# STM32F303 register map
File version: 1.8
CPU: CM4 r1p0, little endian, MPU, FPU, 3 interrupt priority bits
Registers are 32-bit, read-write, reset 0x0 unless marked. A register's access mark holds for its fields unless they carry their own. Offsets are from the block's base; [hi:lo] are bit positions; {n}, {i} and the like mark numbered series; 'fields as' and 'values as' point back to an identical list.

## ADC1_2 — Analog-to-Digital Converter
Base 0x50000300
Same registers: ADC3_4 0x50000700
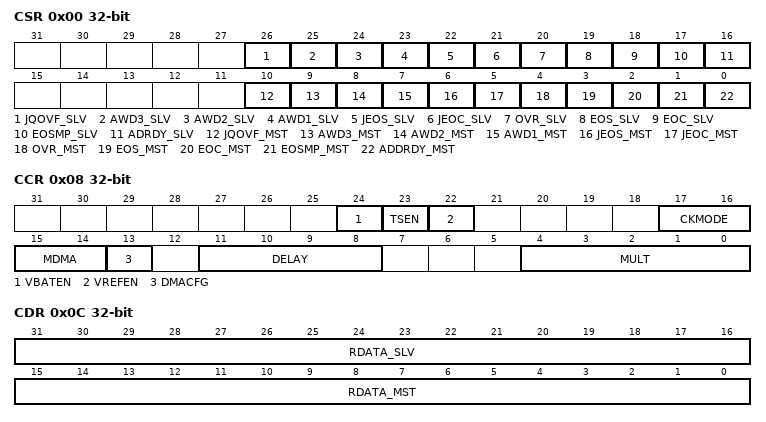
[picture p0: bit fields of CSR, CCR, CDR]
0x00 CSR ro — ADC Common status register
  [26] JQOVF_SLV — Injected Context Queue Overflow flag of the slave ADC
  [25] AWD3_SLV — Analog watchdog 3 flag of the slave ADC
  [24] AWD2_SLV — Analog watchdog 2 flag of the slave ADC
  [23] AWD1_SLV — Analog watchdog 1 flag of the slave ADC
  [22] JEOS_SLV — End of injected sequence flag of the slave ADC
  [21] JEOC_SLV — End of injected conversion flag of the slave ADC
  [20] OVR_SLV — Overrun flag of the slave ADC
  [19] EOS_SLV — End of regular sequence flag of the slave ADC
  [18] EOC_SLV — End of regular conversion of the slave ADC
  [17] EOSMP_SLV
  [16] ADRDY_SLV
  [10] JQOVF_MST
  [9] AWD3_MST
  [8] AWD2_MST
  [7] AWD1_MST
  [6] JEOS_MST
  [5] JEOC_MST
  [4] OVR_MST
  [3] EOS_MST
  [2] EOC_MST
  [1] EOSMP_MST
  [0] ADDRDY_MST
0x08 CCR — ADC common control register
  [24] VBATEN — VBAT enable
  [23] TSEN — Temperature sensor enable
  [22] VREFEN — VREFINT enable
  [17:16] CKMODE — ADC clock mode
  [15:14] MDMA — Direct memory access mode for multi ADC mode
  [13] DMACFG — DMA configuration (for multi-ADC mode)
  [11:8] DELAY — Delay between 2 sampling phases
  [4:0] MULT — Multi ADC mode selection
0x0C CDR ro — ADC common regular data register for dual and triple modes
  [31:16] RDATA_SLV — Regular data of the slave ADC
  [15:0] RDATA_MST — Regular data of the master ADC

## FMC — Flexible memory controller
Base 0xA0000400
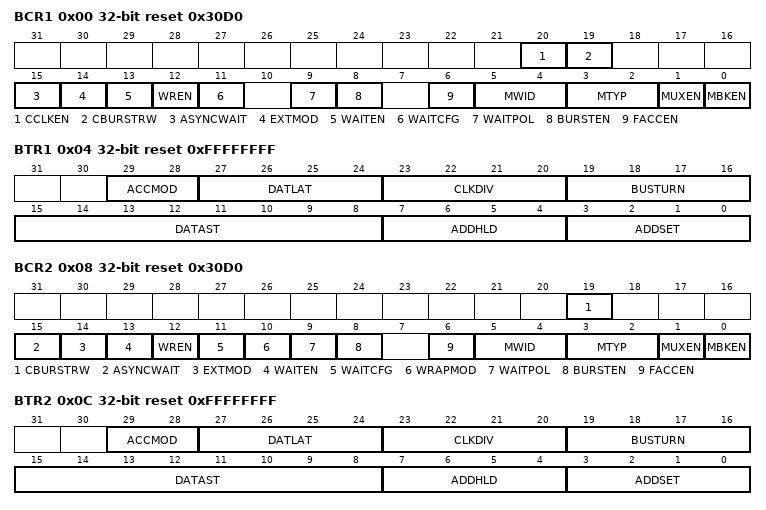
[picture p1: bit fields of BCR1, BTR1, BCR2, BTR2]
0x00 BCR1 reset 0x30D0 — SRAM/NOR-Flash chip-select control register 1
  [20] CCLKEN, [19] CBURSTRW, [15] ASYNCWAIT, [14] EXTMOD, [13] WAITEN, [12] WREN, [11] WAITCFG, [9] WAITPOL, [8] BURSTEN, [6] FACCEN, [5:4] MWID, [3:2] MTYP, [1] MUXEN, [0] MBKEN
0x04 BTR1 reset 0xFFFFFFFF — SRAM/NOR-Flash chip-select timing register 1
  [29:28] ACCMOD, [27:24] DATLAT, [23:20] CLKDIV, [19:16] BUSTURN, [15:8] DATAST, [7:4] ADDHLD, [3:0] ADDSET
0x08 BCR2 reset 0x30D0 — SRAM/NOR-Flash chip-select control register 2
  [19] CBURSTRW, [15] ASYNCWAIT, [14] EXTMOD, [13] WAITEN, [12] WREN, [11] WAITCFG, [10] WRAPMOD, [9] WAITPOL, [8] BURSTEN, [6] FACCEN, [5:4] MWID, [3:2] MTYP, [1] MUXEN, [0] MBKEN
0x0C BTR2 reset 0xFFFFFFFF — SRAM/NOR-Flash chip-select timing register 2
  fields as BTR1
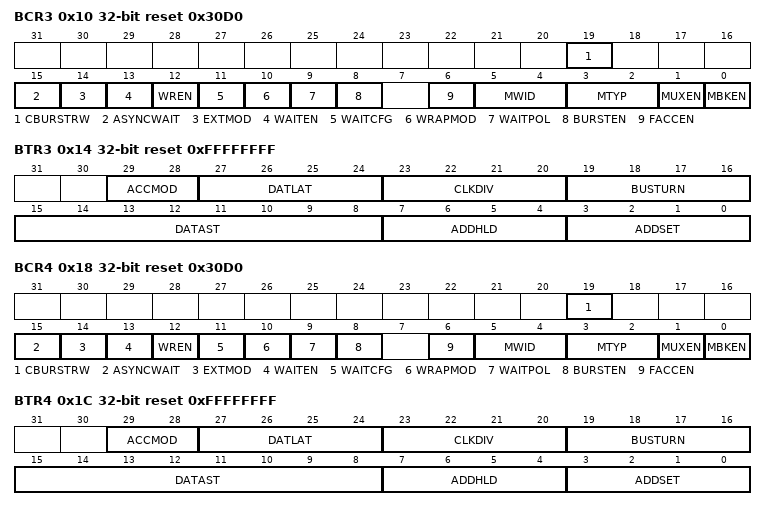
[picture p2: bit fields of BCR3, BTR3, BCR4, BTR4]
0x10 BCR3 reset 0x30D0 — SRAM/NOR-Flash chip-select control register 3
  fields as BCR2
0x14 BTR3 reset 0xFFFFFFFF — SRAM/NOR-Flash chip-select timing register 3
  fields as BTR1
0x18 BCR4 reset 0x30D0 — SRAM/NOR-Flash chip-select control register 4
  fields as BCR2
0x1C BTR4 reset 0xFFFFFFFF — SRAM/NOR-Flash chip-select timing register 4
  fields as BTR1
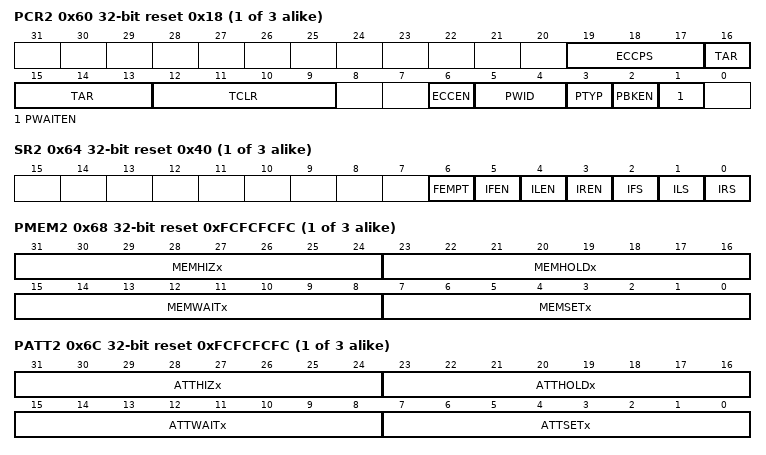
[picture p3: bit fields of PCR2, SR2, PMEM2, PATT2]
{0x20+0x20*i} PCR{i} reset 0x18 (i=2..4) — PC Card/NAND Flash control register {i}
  [19:17] ECCPS, [16:13] TAR, [12:9] TCLR, [6] ECCEN, [5:4] PWID, [3] PTYP, [2] PBKEN, [1] PWAITEN
{0x24+0x20*i} SR{i} access per field reset 0x40 (i=2..4) — FIFO status and interrupt register {i}
  [6] FEMPT ro, [5] IFEN rw, [4] ILEN rw, [3] IREN rw, [2] IFS rw, [1] ILS rw, [0] IRS rw
{0x28+0x20*i} PMEM{i} reset 0xFCFCFCFC (i=2..4) — Common memory space timing register {i}
  [31:24] MEMHIZx, [23:16] MEMHOLDx, [15:8] MEMWAITx, [7:0] MEMSETx
{0x2C+0x20*i} PATT{i} reset 0xFCFCFCFC (i=2..4) — Attribute memory space timing register {i}
  [31:24] ATTHIZx, [23:16] ATTHOLDx, [15:8] ATTWAITx, [7:0] ATTSETx
0x74 ECCR2 ro — ECC result register 2
  [31:0] ECCx
0x94 ECCR3 ro — ECC result register 3
  [31:0] ECCx
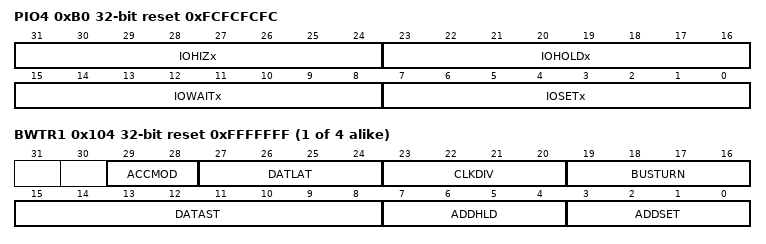
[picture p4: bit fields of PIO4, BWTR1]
0xB0 PIO4 reset 0xFCFCFCFC — I/O space timing register 4
  [31:24] IOHIZx, [23:16] IOHOLDx, [15:8] IOWAITx, [7:0] IOSETx
{0xFC+8i} BWTR{i} reset 0xFFFFFFF (i=1..4) — SRAM/NOR-Flash write timing registers {i}
  [29:28] ACCMOD
  [27:24] DATLAT
  [23:20] CLKDIV
  [19:16] BUSTURN — Bus turnaround phase duration
  [15:8] DATAST
  [7:4] ADDHLD
  [3:0] ADDSET

## Notices in the file
Copyright (c) 2023 STMicroelectronics.
SPDX-License-Identifier: Apache-2.0
Licensed under the Apache License, Version 2.0 (the "License");
you may not use this file except in compliance with the License.
You may obtain a copy of the License at
http://www.apache.org/licenses/LICENSE-2.0
Unless required by applicable law or agreed to in writing, software
distributed under the License is distributed on an "AS IS" BASIS,
WITHOUT WARRANTIES OR CONDITIONS OF ANY KIND, either express or implied.
See the License for the specific language governing permissions and
limitations under the License.
